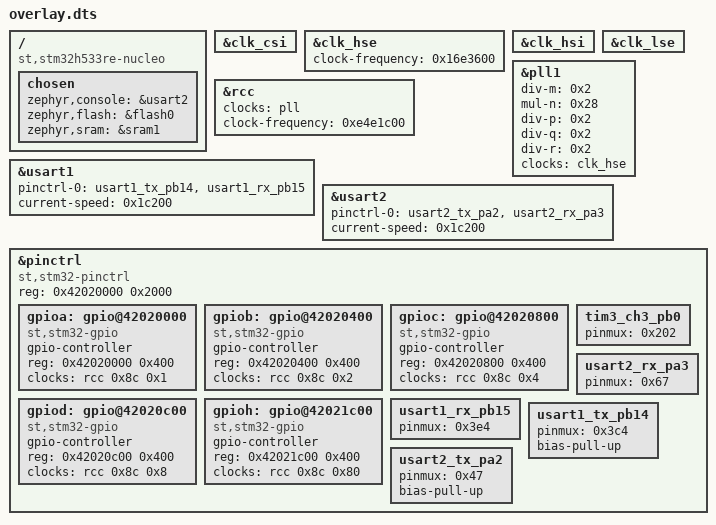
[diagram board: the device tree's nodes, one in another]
/ {
	compatible = "st,stm32h533re-nucleo";
	chosen {
		zephyr,console = &usart2;
		zephyr,flash = &flash0;
		zephyr,sram = &sram1;
	};
};
&clk_csi{
	status = "okay";
};
&clk_hse{
	status = "okay";
	clock-frequency = < 0x16e3600 >;
};
&clk_hsi{
	status = "okay";
};
&clk_lse{
	status = "okay";
};
&pll1{
	status = "okay";
	div-m = < 0x2 >;
	mul-n = < 0x28 >;
	div-p = < 0x2 >;
	div-q = < 0x2 >;
	div-r = < 0x2 >;
	clocks = < &clk_hse >;
};
&rcc{
	clocks = < &pll >;
	clock-frequency = < 0xe4e1c00 >;
};
&usart1{
	status = "okay";
	pinctrl-0 = < &usart1_tx_pb14 &usart1_rx_pb15 >;
	pinctrl-names = "default";
	current-speed = < 0x1c200 >;
};
&usart2{
	status = "okay";
	pinctrl-0 = < &usart2_tx_pa2 &usart2_rx_pa3 >;
	pinctrl-names = "default";
	current-speed = < 0x1c200 >;
};
&pinctrl{
	compatible = "st,stm32-pinctrl";
	#address-cells = < 0x1 >;
	#size-cells = < 0x1 >;
	reg = < 0x42020000 0x2000 >;
	gpioa: gpio@42020000 {
		compatible = "st,stm32-gpio";
		gpio-controller;
		#gpio-cells = < 0x2 >;
		reg = < 0x42020000 0x400 >;
		clocks = < &rcc 0x8c 0x1 >;
	};
	gpiob: gpio@42020400 {
		compatible = "st,stm32-gpio";
		gpio-controller;
		#gpio-cells = < 0x2 >;
		reg = < 0x42020400 0x400 >;
		clocks = < &rcc 0x8c 0x2 >;
	};
	gpioc: gpio@42020800 {
		compatible = "st,stm32-gpio";
		gpio-controller;
		#gpio-cells = < 0x2 >;
		reg = < 0x42020800 0x400 >;
		clocks = < &rcc 0x8c 0x4 >;
	};
	gpiod: gpio@42020c00 {
		compatible = "st,stm32-gpio";
		gpio-controller;
		#gpio-cells = < 0x2 >;
		reg = < 0x42020c00 0x400 >;
		clocks = < &rcc 0x8c 0x8 >;
	};
	gpioh: gpio@42021c00 {
		compatible = "st,stm32-gpio";
		gpio-controller;
		#gpio-cells = < 0x2 >;
		reg = < 0x42021c00 0x400 >;
		clocks = < &rcc 0x8c 0x80 >;
	};
	tim3_ch3_pb0: tim3_ch3_pb0 {
		pinmux = < 0x202 >;
	};
	usart1_rx_pb15: usart1_rx_pb15 {
		pinmux = < 0x3e4 >;
	};
	usart2_rx_pa3: usart2_rx_pa3 {
		pinmux = < 0x67 >;
	};
	usart1_tx_pb14: usart1_tx_pb14 {
		pinmux = < 0x3c4 >;
		bias-pull-up;
	};
	usart2_tx_pa2: usart2_tx_pa2 {
		pinmux = < 0x47 >;
		bias-pull-up;
	};
};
